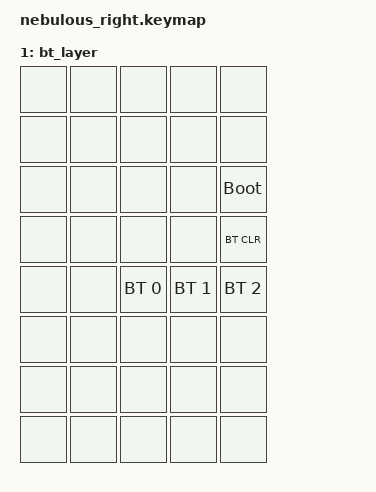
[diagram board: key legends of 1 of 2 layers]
#include <behaviors.dtsi>
#include <dt-bindings/zmk/keys.h>
#include <dt-bindings/zmk/bt.h>

/ {  
    keymap {
        compatible = "zmk,keymap";

        default_layer {
            bindings = <
                &bootloader  &kp N7  &kp N8  &kp N9
                &kp Y   &kp U   &kp I   &kp O  &kp P
                &kp H   &kp J   &kp K   &kp L  &kp RET
                &kp N   &kp M   &kp SEMI   &kp DOT  &kp COLON
                &kp U   &kp V   &kp W   &kp X &kp Y
                &kp SPACE   &kp N1
                &kp RET 
            >;
            
        };
                bt_layer {
            bindings = <
                &none 	&none   &none   &none 	&none
                &none 	&none   &none   &none 	&none
                &none   &none   &none   &none   &bootloader
                &none   &none   &none   &none   &bt BT_CLR
                &none   &none   &bt BT_SEL 0    &bt BT_SEL 1     &bt BT_SEL 2 
                &none 	&none   &none   &none 	&none
                &none 	&none   &none   &none 	&none
                &none 	&none   &none   &none 	&none
            >;
        };
    };
};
